AUTOSAR XML (schema 4-2-2)
package /EB/SoftwareComponents
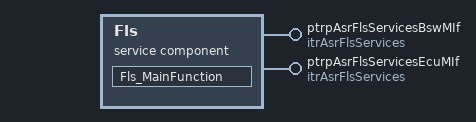
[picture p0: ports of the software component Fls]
  service sw component type Fls: category=ASR_Interfaces
    provide port ptrpAsrFlsServicesBswMIf: provided-interface=itrAsrFlsServices
    provide port ptrpAsrFlsServicesEcuMIf: provided-interface=itrAsrFlsServices
    behavior Fls_IB: handle-termination-and-restart=NO-SUPPORT
      runnable Fls_MainFunction
package /EB/TriggerInterfaces
  trigger interface itrAsrFlsServices
    trigger Fls_Init: trigger-period={cse-code=1000, cse-code-factor=0}
    trigger Fls_MainFunction: trigger-period={cse-code=1000, cse-code-factor=0}
